# R7KA8M2AD register map
Vendor: Renesas Electronics Corporation; Series: RA8; File version: 1.10.02
CPU: CM85 r0p2, little endian, MPU, FPU, VTOR, 4 interrupt priority bits, 96 interrupts
Registers are 32-bit, read-write, reset 0x0 unless marked. A register's access mark holds for its fields unless they carry their own. Offsets are from the block's base; [hi:lo] are bit positions; {n}, {i} and the like mark numbered series; 'fields as' and 'values as' point back to an identical list.

## SCI0_B — Serial Communication Interface
Base 0x40358000
Same registers: SCI{n}_B {0x40358000+0x100*n} (n=1..9), SCI{n}_B_NS {0x50358000+0x100*n} (n=0..9)
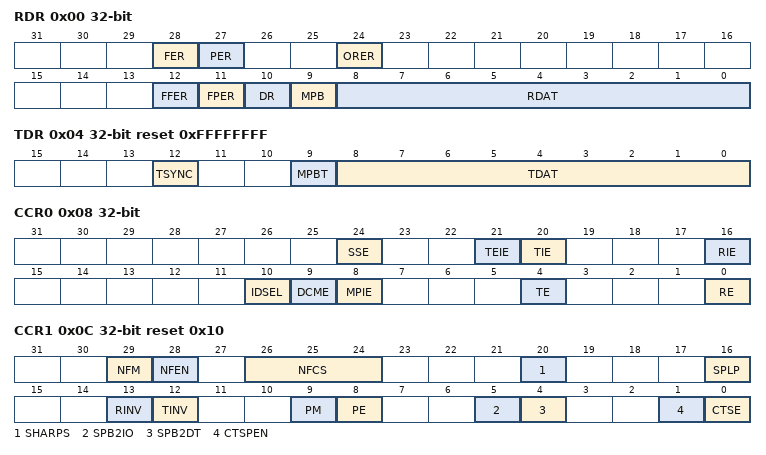
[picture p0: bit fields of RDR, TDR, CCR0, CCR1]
0x00 RDR ro — Receive Data Register
  [28] FER — Framing error flag
  [27] PER — Parity error flag
  [24] ORER — Overrun Error flag
  [12] FFER — FIFO framing error flag
    0=There is no framing error in the data read from the receive-FIFO; 1=There is framing error in the data read from the receive-FIFO
  [11] FPER — FIFO parity error flag
    0=There is no parity error in the data read from the receive-FIFO; 1=There is parity error in the data read from the receive-FIFO
  [10] DR — Receive data ready flag
  [9] MPB — Multi-processor flag
    0=Data transmission cycles; 1=ID transmission cycles
  [8:0] RDAT — Serial receive data
0x04 TDR reset 0xFFFFFFFF — Transmit Data Register
  [12] TSYNC — Transmit SYNC data
    0=The Start Bit is transmitted as DATA SYNC; 1=The Start Bit is transmitted as COMMAND SYNC
  [9] MPBT — Multi-processor transfer bit flag
    0=Data transmission cycles; 1=ID transmission cycles
  [8:0] TDAT — Serial transmit data
0x08 CCR0 — Common Control Register 0
  [24] SSE — SSn Pin Function Enable
    0=SSn pin function is disabled; 1=SSn pin function is enabled
  [21] TEIE — Transmit End Interrupt Enable
    0=SCIn_TEI interrupt request is disabled; 1=SCIn_TEI interrupt request is enabled
  [20] TIE — Transmit Interrupt Enable
    0=SCIn_TXI interrupt request is disabled; 1=SCIn_TXI interrupt request is enabled
  [16] RIE — Receive Interrupt Enable
    0=SCIn_RXI and SCIn_ERI interrupt requests are disabled; 1=SCIn_RXI and SCIn_ERI interrupt requests are enabled
  [10] IDSEL — ID Frame Select
    0=Compare data irrespective of the value of the MPB bit; 1=Compare data only when the MPB bit is 1 (ID frame)
  [9] DCME — Data Compare Match Enable
    0=Address match function is disabled; 1=Address match function is enabled
  [8] MPIE — Multi-Processor Interrupt Enable
    0=Non-multi-processor reception; 1=Multi-processor reception When the data with the multi-processor bit set to 0 is received, the data is not read, and setting the status flags to 1 is disabled. When the data with the multi-processor bit set to 1 is received, the MPIE bit is automatically cleared to 0, and non-multi-processor reception is resumed. If you want to continue receiving operation using the multiprocessor function, set this bit to 1 sufficiently earlier than receiving the STOP bit of the next received frame (consider the synchronization delay time).
  [4] TE — Transmit Enable
    0=Serial transmission is disabled; 1=Serial transmission is enabled
  [0] RE — Receive Enable
    0=Serial reception is disabled; 1=Serial reception is enabled
0x0C CCR1 reset 0x10 — Common Control Register 1
  [29] NFM — Noise Filter Mode
    0=3-point matching mode; 1=Majority vote mode
  [28] NFEN — Digital Noise Filter Function Enable
    0=In Asynchronous, Manchester, Simple LIN modes: Disable noise cancellation function for RXDn input signal In Simple IIC mode: Disable noise cancellation function for SCLn and SDAn input signals; 1=In Asynchronous, Manchester, Simple LIN modes: Enable noise cancellation function for RXDn input signal In Simple IIC mode: Enable noise cancellation function for SCLn and SDAn input signals
  [26:24] NFCS — Noise Filter Clock Select
    0=The base clock signal divided by 1; 1=The on-chip baud rate generator source clock divided by 1; 2=The on-chip baud rate generator source clock divided by 2; 3=The on-chip baud rate generator source clock divided by 4; 4=The on-chip baud rate generator source clock divided by 8; other=others (Setting prohibited)
  [20] SHARPS — Half-Duplex Communication Select
    0=TXDn pin, RXDn pin independent; 1=TXDn/RXDn pin combination use (half-duplex communication using TXDn pin)
  [16] SPLP — Loopback Control
    0=Normal mode; 1=Loopback mode
  [13] RINV — RXD Invert
    0=Received data from RXDn is not inverted and input; 1=Received data from RXDn is inverted and input
  [12] TINV — TXD Invert
    0=Transmit data is not inverted and output to TXDn; 1=Transmit data is inverted and output to TXDn
  [9] PM — Parity Mode
    0=Selects even parity; 1=Selects odd parity
  [8] PE — Parity Enable
    0=When transmitting: Do not add parity bit When receiving: Do not check parity bit; 1=When transmitting: Add parity bit When receiving: Check parity bit
  [5] SPB2IO — Serial Port Break I/O
    0=The value of SPB2DT bit is not output in TXDn pin; 1=The value of SPB2DT bit is output in TXDn pin
  [4] SPB2DT — Serial Port Break Data Select
    0=When TINV is 0, low level is output in TXDn pin. When TINV is 1, high level is output in TXDn pin.; 1=When TINV is 0, high level is output in TXDn pin. When TINV is 1, low level is output in TXDn pin.
  [1] CTSPEN — CTS External Pin Enable
    0=Alternate setting to use CTS and RTS functions as either 1 pin; 1=Dedicated setting for separately using CTS and RTS functions with 2 pins
  [0] CTSE — CTS Enable
    0=CTS function is disabled (RTS output function is enabled); 1=CTS function is enabled
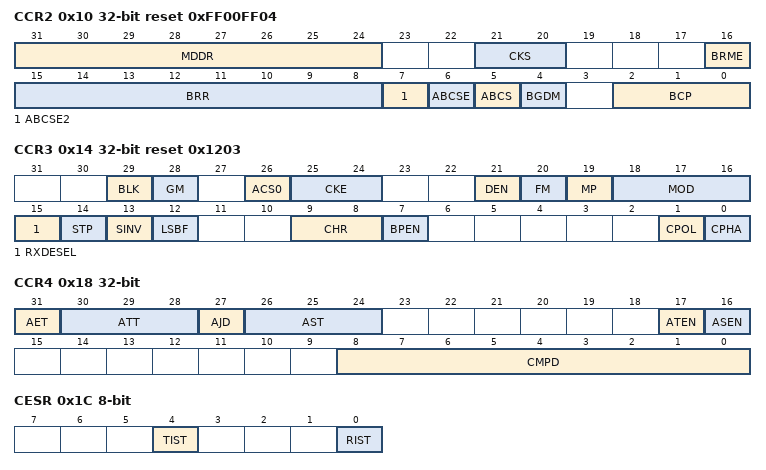
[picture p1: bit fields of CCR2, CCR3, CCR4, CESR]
0x10 CCR2 reset 0xFF00FF04 — Common Control Register 2
  [31:24] MDDR — Modulation Duty Setting
  [21:20] CKS — Clock Select
    0=TCLK clock (n = 0); 1=TCLK/4 clock (n = 1); 2=TCLK/16 clock (n = 2); 3=TCLK/64 clock (n = 3)
  [16] BRME — Bit Rate Modulation Enable
    0=Bit rate modulation function is disabled; 1=Bit rate modulation function is enabled
  [15:8] BRR — Bit Rate Setting
  [7] ABCSE2 — Asynchronous Mode Extended Base Clock Select 2
    0=Clock cycles for 1-bit period is decided with combination between CCR2.BGDM and CCR2.ABCS; 1=Baud rate is 4 base clock cycles for 1-bit period and the clock of a double frequency is output from the baud rate generator
  [6] ABCSE — Asynchronous Mode Extended Base Clock Select
    0=Clock cycles for 1-bit period is determined by combination between CCR2.BGDM and CCR2.ABCS; 1=Baud rate is 6 base clock cycles for 1-bit period and the clock of a double frequency is output from the baud rate generator
  [5] ABCS — Asynchronous Mode Base Clock Select
    0=Selects 16 base clock cycles for 1-bit period; 1=Selects 8 base clock cycles for 1-bit period
  [4] BGDM — Baud Rate Generator Double-Speed Mode Select
    0=Baud rate generator outputs the clock with single frequency; 1=Baud rate generator outputs the clock with doubled frequency
  [2:0] BCP — Base Clock Pulse
    0=93 clock cycles (S = 93); 1=128 clock cycles (S = 128); 2=186 clock cycles (S = 186); 3=512 clock cycles (S = 512); 4=32 clock cycles (S = 32) (Initial value); 5=64 clock cycles (S = 64); 6=372 clock cycles (S = 372); 7=256 clock cycles (S = 256)
0x14 CCR3 reset 0x1203 — Common Control Register 3
  [29] BLK — Block Transfer Mode
    0=Non-block transfer mode operation; 1=Block transfer mode operation
  [28] GM — GSM Mode
    0=Non-GSM mode operation; 1=GSM mode operation
  [26] ACS0 — Asynchronous Mode Clock Source Select
    0=External clock input; 1=Logical AND of compare matches output from the internal GPT
  [25:24] CKE — Clock Enable
    0=In Asynchronous mode:On-chip baud rate generatorThe SCKn pin is available for use as an I/O port in accord with the I/O port settings. In Manchester mode and Simple LIN mode:On-chip baud rate generatorThe SCKn pin functions as I/O port. In Clock synchronous mode and Simple SPI mode:Internal clock (master operation)The SCKn pin functions as the clock output pin. In Smart card interface mode and when CCR3.GM = 0:Output disabled (the SCKn pin is available for use as an I/O port in accord with the I/O port settings). In Smart card interface mode and when CCR3.GM = 1:Output fixed low; 1=In Asynchronous mode:On-chip baud rate generatorThe clock with the same frequency as the bit rate is output from the SCKn pin. In Manchester mode and Simple LIN mode:Prohibited In Clock synchronous mode and Simple SPI mode:Internal clock (master operation)The SCKn pin functions as the clock output pin. In Smart card interface mode and when CCR3.GM = 0:Clock output In Smart card interface mode and when CCR3.GM = 1:Clock output; 2=In Asynchronous mode:External clock or GPT clock When using the external clock16 times the bit rate should be input from the SCKn pin when CCR2.ABCS bit is 0. Input a clock signal with a frequency 8 times the bit rate when the CCR2.ABCS bit is 1.When using the GPT clockThe SCKn pin is available for use as an I/O port in accord with the I/O port settings when the GPT clock is used. In Manchester mode and Simple LIN mode:Prohibited In Clock synchronous mode and Simple SPI mode:External clock (slave operation)The SCKn pin functions as the clock input pin. In Smart card interface mode and when CCR3.GM = 0:Prohibited In Smart card interface mode and when CCR3.GM = 1:Output fixed high; 3=In Asynchronous mode:External clock or GPT clock When using the external clock16 times the bit rate should be input from the SCKn pin when CCR2.ABCS bit is 0. Input a clock signal with a frequency 8 times the bit rate when the CCR2.ABCS bit is 1.When using the GPT clock The SCKn pin is available for use as an I/O port in accord with the I/O port settings when the GPT clock is used. In Manchester mode and Simple LIN mode:Prohibited In Clock synchronous mode and Simple SPI mode:External clock (slave operation)The SCKn pin functions as the clock input pin. In Smart card interface mode and when CCR3.GM = 0:Prohibited In Smart card interface mode and when CCR3.GM = 1:Clock output
  [21] DEN — Driver Enable
    0=RS-485 driver control function disabled; 1=RS-485 driver control function enabled
  [20] FM — FIFO Mode Select
    0=TDR register and RDR register are non-FIFO buffer configuration; 1=TDR register and RDR register are FIFO buffer configuration
  [19] MP — Multi-Processor Mode
    0=Multi-processor communications function is disabled; 1=Multi-processor communications function is enabled
  [18:16] MOD — Communication Mode Select
    0=Asynchronous mode (multi-processor mode); 1=Smart card interface mode; 2=Clock synchronous mode; 3=Simple SPI mode; 4=Simple IIC mode; 5=Manchester mode; 6=Simple LIN mode; 7=Setting prohibited
  [15] RXDESEL — Asynchronous Start Bit Edge Detection Select
    0=The low level on the RXDn pin is detected as the start bit; 1=A falling edge on the RXDn pin is detected as the start bit
  [14] STP — Stop Bit Length
    0=1 stop bit/break delimiter length is 1-bit; 1=2 stop bits/break delimiter length is 2-bit
  [13] SINV — Transmitted/Received Data Invert
    0=TDR contents are transmitted to TSR as is. RSR contents are stored to RDR as is.; 1=TDR contents are inverted before being transmitted to TSR. RSR contents are inverted and stored to RDR.
  [12] LSBF — LSB First select
    0=MSB-first; 1=LSB-first
  [9:8] CHR — Character Length
    0=Transmit/receive in 9-bit data length; 1=Transmit/receive in 9-bit data length; 2=Transmit/receive in 8-bit data length (initial value); 3=Transmit/receive in 7-bit data length
  [7] BPEN — Synchronizer Bypass Enable
    0=Synchronizer circuit is not bypassed; 1=Synchronizer circuit is bypassed
  [1] CPOL — Clock Polarity Select
    0=SCKn in idle state is 0; 1=SCKn in idle state is 1
  [0] CPHA — Clock Phase Select
    0=Data is sampled at an odd edge and changes at an even edge (clock is delayed); 1=Data changes at an odd edge and is sampled at an even edge (clock is not delayed)
0x18 CCR4 — Common Control Register 4
  [31] AET — Adjustment Edge for Transmit Timing
    0=When CCR1.TINV is 0, adjust the rising edge timing. When CCR1.TINV is 1, adjust the falling edge timing.; 1=When CCR1.TINV is 0, adjust the falling edge timing. When CCR1.TINV is 1, adjust the rising edge timing.
  [30:28] ATT — Adjustment Value for Transmit Timing
  [27] AJD — Adjustment Direction for Receive Sampling Timing
    0=The sampling timing is adjusted backward to the middle of bit; 1=The sampling timing is adjusted forward to the middle of bit
  [26:24] AST — Adjustment Value for Receive Sampling Timing
    {v}={v+1}-TCLK delay (v=0..3); other=Others (Setting prohibited)
  [17] ATEN — Adjust Transmit Timing Enable
    0=Adjust transmit timing disabled; 1=Adjust transmit timing enabled
  [16] ASEN — Adjust Receive Sampling Timing Enable
    0=Adjust sampling timing disabled; 1=Adjust sampling timing enabled
  [8:0] CMPD — Compare Match Data
0x1C CESR 8-bit ro — Communication Enable Status Register
  [4] TIST — TE Internal Status
    0=TE signal internal state value 0; 1=TE signal internal state value 1
  [0] RIST — RE Internal Status
    0=RE signal internal state value 0; 1=RE signal internal state value 1
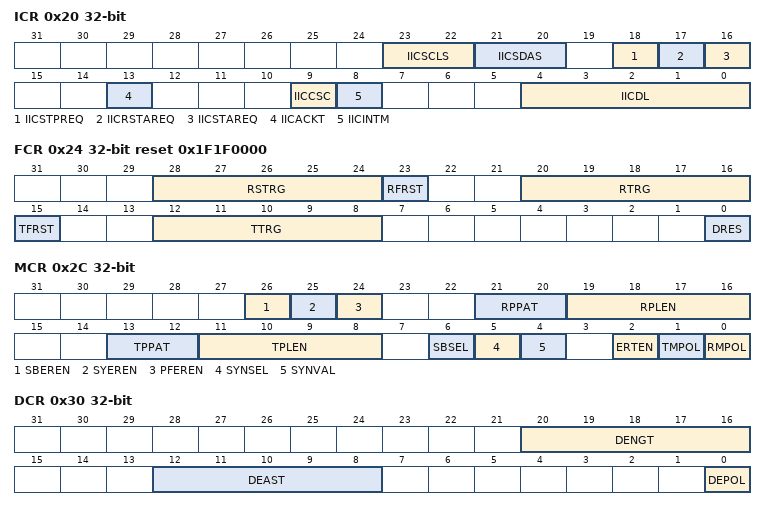
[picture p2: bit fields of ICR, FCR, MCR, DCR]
0x20 ICR — Simple IIC Control Register
  [23:22] IICSCLS — SCL Output Select
    0=Serial clock output; 1=Generate a start, restart, or stop condition; 2=Output the low level on the SCLn pin; 3=Place the SCLn pin in the high-impedance state
  [21:20] IICSDAS — SDA Output Select
    0=Serial data output; 1=Generate a start, restart, or stop condition; 2=Output the low level on the SDAn pin; 3=Place the SDAn pin in the high-impedance state
  [18] IICSTPREQ — Stop Condition Generation
    0=A stop condition is not generated; 1=A stop condition is generated
  [17] IICRSTAREQ — Restart Condition Generation
    0=A restart condition is not generated; 1=A restart condition is generated
  [16] IICSTAREQ — Start Condition Generation
    0=A start condition is not generated; 1=A start condition is generated
  [13] IICACKT — ACK Transmission Data
    0=ACK transmission; 1=NACK transmission and reception of ACK/NACK
  [9] IICCSC — Clock Synchronization
    0=No synchronization with the clock signal; 1=Synchronization with the clock signal
  [8] IICINTM — IIC Interrupt Mode Select
    0=Use ACK/NACK interrupts; 1=Use reception and transmission interrupts
  [4:0] IICDL — SDA Delay Output Select
0x24 FCR reset 0x1F1F0000 — FIFO Control Register
  [28:24] RSTRG — RTS Output Active Trigger Number Select
  [23] RFRST wo — Receive FIFO Data Register Reset
    0=When set, this bit is invalid and does not affect operation; 1=The number of data stored in Receive-FIFO(RDR register) is 0
  [20:16] RTRG — Receive FIFO Data Trigger Number
  [15] TFRST wo — Transmit FIFO Data Register Reset
    0=When set, this bit is invalid and does not affect operation; 1=The number of data stored in Transmit-FIFO (TDR register) is 0
  [12:8] TTRG — Transmit FIFO Data Trigger Number
  [0] DRES — Receive Data Ready Error Select Bit
    0=Reception data full interrupt (SCIn_RXI); 1=Receive error interrupt (SCIn_ERI)
0x2C MCR — Manchester Control Register
  [26] SBEREN — Start Bit Error Enable
    0=Does not handle a start bit error as an interrupt source; 1=Handles a start bit error as an interrupt source
  [25] SYEREN — Receive SYNC Error Enable
    0=Does not handle a receive SYNC error as an interrupt source; 1=Handles a receive SYNC error as an interrupt source
  [24] PFEREN — Preface Error Enable
    0=Does not handle a preface error as an interrupt source; 1=Handles a preface error as an interrupt source
  [21:20] RPPAT — Receive Preface Pattern
    0=ALL ZERO; 1=ZERO ONE; 2=ONE ZERO; 3=ALL ONE
  [19:16] RPLEN — Receive Preface Length
    0=Disables the receive preface generation; other=Others (Receive preface length (bit length))
  [13:12] TPPAT — Transmit Preface Pattern
    0=ALL ZERO; 1=ZERO ONE; 2=ONE ZERO; 3=ALL ONE
  [11:8] TPLEN — Transmit Preface Length
    0=Disables the transmit preface generation; other=Others (Transmit preface length (bit length))
  [6] SBSEL — Start Bit Select
    0=The start bit area consists of one bit; 1=The start bit area consists of three bits (COMMAND SYNC or DATA SYNC)
  [5] SYNSEL — SYNC Select
    0=The start bit pattern is set with the SYNVAL bit; 1=The start bit pattern is set with the TSYNC bit
  [4] SYNVAL — SYNC value Setting
  [2] ERTEN — Manchester Edge Retiming Enable
    0=Disables the receive retiming function; 1=Enables the receive retiming function
  [1] TMPOL — Polarity of Transmit Manchester Code
    0=Logic 0 is coded as a zero-to-one transition in Manchester code Logic 1 is coded as a one-to-zero transition in Manchester code; 1=Logic 0 is coded as a one-to-zero transition in Manchester code Logic 1 is coded as a zero-to-one transition in Manchester code
  [0] RMPOL — Polarity of Received Manchester Code
    values as TMPOL
0x30 DCR — Driver Control Register
  [20:16] DENGT — Driver Negate Time
  [12:8] DEAST — Driver Assertion Time
  [0] DEPOL — Driver Effective Polarity Select
    0=The DEn signal is active-high; 1=The DEn signal is active-low
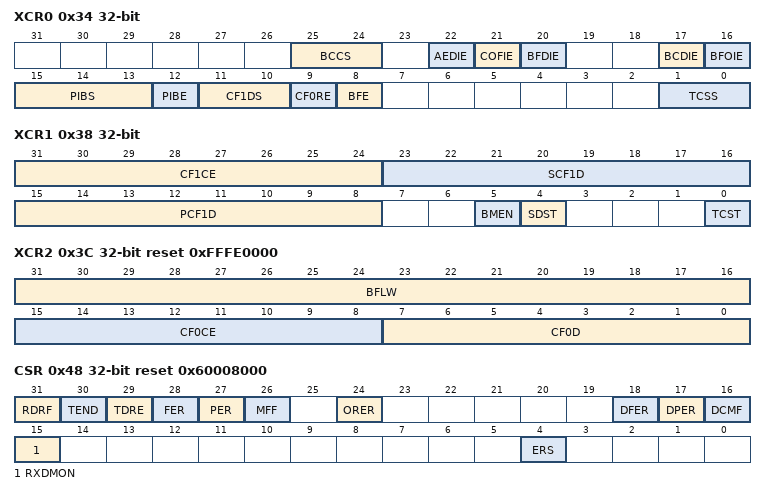
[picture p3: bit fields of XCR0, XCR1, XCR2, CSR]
0x34 XCR0 — Simple LIN Control Register 0
  [25:24] BCCS — Bus Conflict Detection Clock Selection
    0=Base clock; 1=Base clock/2; 2=Base clock/4; 3=Setting prohibited
  [22] AEDIE — Active Edge Detection Interrupt Enable
    0=Active edge detection interrupt disabled; 1=Active edge detection interrupt enabled
  [21] COFIE — Counter Overflow Interrupt Enable
    0=Counter overflow is not included in SCIn_ERI interrupt factor; 1=Counter overflow is included in SCIn_ERI interrupt factor
  [20] BFDIE — Break Field Detection Interrupt Enable
    0=Break Field detection interrupt disabled; 1=Break Field detection interrupt enabled
  [17] BCDIE — Bus Conflict Detection Interrupt Enable
    0=Bus conflict detection is not included in SCIn_ERI interrupt factor; 1=Bus conflict detection is included in SCIn_ERI interrupt factor
  [16] BFOIE — Break Field Output Completion Interrupt Enable
    0=Break Field output completion is not included in SCIn_TXI interrupt factor; 1=Break Field output completion is included in SCIn_TXI interrupt factor
  [15:13] PIBS — Priority Interrupt Bit Select
    {v}=Bit {v} of Control Field 1 (v=0..7)
  [12] PIBE — Priority Interrupt Bit Enable
    0=Priority interrupt bit disabled; 1=Priority interrupt bit enabled
  [11:10] CF1DS — Control Field1 Compare Data Select
    0=Select XCR1.PCF1D[7:0] as the compare data; 1=Select XCR1.SCF1D[7:0] as the compare data; 2=Select both XCR1.PCF1D[7:0] and XCR1.SCF1D[7:0] as the compare data; 3=Setting prohibited
  [9] CF0RE — Control Field 0 Enable
    0=No Control Field 0; 1=With Control Field 0
  [8] BFE — Break Field Enable
    0=No Break Field; 1=With Break Field
  [1:0] TCSS — Timer Count Clock Source Selection
    1=TCLK/4; 2=TCLK/16; 3=TCLK/64
0x38 XCR1 — Simple LIN Control Register 1
  [31:24] CF1CE — Control Field 1 Compare Bit Enable
    0=Control Field 1 bit N compare disabled; 1=Control Field 1 bit N compare enabled
  [23:16] SCF1D — Secondary Compare Data for Control Field 1
  [15:8] PCF1D — Priority Compare Data for Control Field 1
  [5] BMEN — Bit Rate Measurement Enable
    0=Bit rate measurement disabled; 1=Bit rate measurement enabled
  [4] SDST — Start Frame Detection Enable
    0=Start Frame/Break Field detection disabled; 1=Start Frame/Break Field detection enabled
  [0] TCST — Break Field Output Timer Count Start Trigger
    0=Break Field output timer count stopped; 1=Break Field output timer count start
0x3C XCR2 reset 0xFFFE0000 — Simple LIN Control Register 2
  [31:16] BFLW — Break Field Length Setting
  [15:8] CF0CE — Control Field 0 Compare Bit Enable
    0=Control Field 0 bit N compare disabled; 1=Control Field 0 bit N compare enabled
  [7:0] CF0D — Control Field 0 Compare Data
0x48 CSR ro reset 0x60008000 — Common Status Register
  [31] RDRF — Receive Data Full Flag
    0=Non-FIFO selected (CCR3.FM = 0): No received data is in RDR register FIFO selected (CCR3.FM = 1): The quantity of receive data written in receive-FIFO falls below the specified receive triggering number; 1=Non-FIFO selected (CCR3.FM = 0): Received data is in RDR register FIFO selected (CCR3.FM = 1): The quantity of receive data written in receive-FIFO is equal to or greater than the specified receive triggering number
  [30] TEND — Transmit End Flag
    0=A character is being transmitted or standing by for transmission; 1=Character transfer has been completed, or sending Break Field
  [29] TDRE — Transmit Data Empty Flag
    0=Non-FIFO selected (CCR3.FM = 0): Transmit data is in TDR register FIFO selected (CCR3.FM = 1): The quantity of transmit data written in transmit-FIFO exceeds the specified transmit triggering number; 1=Non-FIFO selected (CCR3.FM = 0): No transmit data is in TDR register FIFO selected (CCR3.FM = 1): The quantity of transmit data written in transmit-FIFO is equal to or less than the specified transmit triggering number
  [28] FER — Framing Error Flag
    0=Non-FIFO selected (CCR3.FM = 0): No framing error occurred FIFO selected (CCR3.FM = 1): No framing error in all received data in receive-FIFO; 1=Non-FIFO selected (CCR3.FM = 0): A framing error has occurred FIFO selected (CCR3.FM = 1): One or more framing errors occurred in received data in receive-FIFO
  [27] PER — Parity Error Flag
    0=Non-FIFO selected (CCR3.FM = 0): No parity error occurred FIFO selected (CCR3.FM = 1): No parity error in all received data in receive-FIFO; 1=Non-FIFO selected (CCR3.FM = 0): A parity error has occurred FIFO selected (CCR3.FM = 1): One or more parity errors occurred in received data in receive-FIFO
  [26] MFF — Mode Fault Error Flag
    0=No mode fault error; 1=Mode fault error
  [24] ORER — Overrun Error Flag
    0=No overrun error occurred; 1=An overrun error has occurred
  [18] DFER — Data Compare Match Framing Error Flag
    0=No framing error occurred at address match detection; 1=A framing error has occurred at address match detection
  [17] DPER — Data Compare Match Parity Error Flag
    0=No parity error occurred at address match detection; 1=A parity error has occurred at address match detection
  [16] DCMF — Data Compare Match Flag
    0=No matched; 1=Matched
  [15] RXDMON — Serial Input Data Monitor Bit
    0=When RINV is 0, RXDn pin is the low level. When RINV is 1, RXDn pin is the high level.; 1=When RINV is 0, RXDn pin is the high level. When RINV is 1, RXDn pin is the low level.
  [4] ERS — Error Signal Status Flag
    0=Error signal low not responded; 1=Error signal low responded
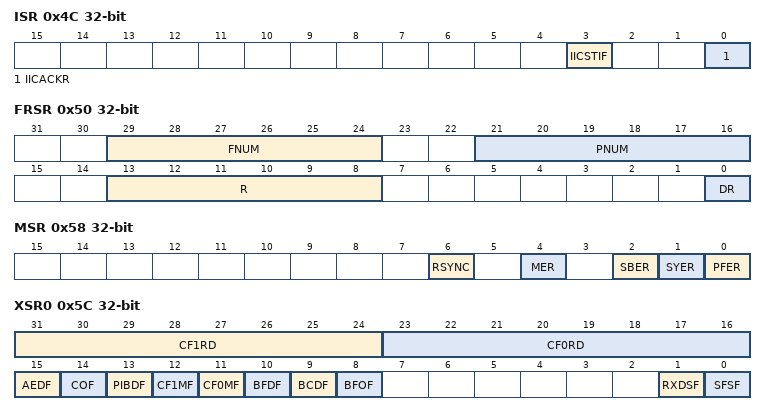
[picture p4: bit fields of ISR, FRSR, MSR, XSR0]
0x4C ISR ro — Simple IIC Status Register
  [3] IICSTIF — Issuing of Start, Restart, or Stop Condition Completed Flag
    0=There are no requests for generating conditions or a condition is being generated; 1=A start, restart, or stop condition is completely generated
  [0] IICACKR — ACK Reception Data Flag
    0=ACK received; 1=NACK received
0x50 FRSR ro — FIFO Receive Status Register
  [29:24] FNUM — Framing Error Count
  [21:16] PNUM — Parity Error Count
  [13:8] R — Receive-FIFO Data Count
  [0] DR — Receive Data Ready Flag
    0=Receiving is in progress, or no received data remains in the receive-FIFO after a successful reception (receive-FIFO is empty); 1=The following receive data is not received for a fixed period after storing data under the threshold in the receive-FIFO
0x54 FTSR ro — FIFO Transmit Status Register
  [5:0] T — Transmit-FIFO Data Count
0x58 MSR ro — Manchester Status Register
  [6] RSYNC — Receive SYNC Data Bit
    0=The received start bit is DATA SYNC; 1=The received start bit is COMMAND SYNC
  [4] MER — Manchester Error Flag
    0=No Manchester error occurred; 1=Manchester error has occurred
  [2] SBER — Start Bit Error Flag
    0=No start bit error detected; 1=Start bit error detected
  [1] SYER — SYNC Error Flag
    0=No receive SYNC error detected; 1=Receive SYNC error detected
  [0] PFER — Preface Error Flag
    0=No preface error detected; 1=Preface error detected
0x5C XSR0 ro — Simple LIN Status Register 0
  [31:24] CF1RD — Control Field 1 received data
  [23:16] CF0RD — Control Field 0 received data
  [15] AEDF — Active Edge Detection Flag
    0=No valid edge detected; 1=Detected a valid edge
  [14] COF — Counter Overflow Flag
    0=Break Field detection counter has not overflowed; 1=Break Field detection counter overflowed
  [13] PIBDF — Priority Interrupt Bit Detection Flag
    0=Priority interrupt bit is not detected; 1=Priority interrupt bit is detected
  [12] CF1MF — Control Field 1 Compare Match Flag
    0=Control Field 1 received data does not match the setting data; 1=Control Field 1 received data matches the setting data
  [11] CF0MF — Control Field 0 Compare Match Flag
    0=Control Field 0 received data does not match the setting data; 1=Control Field 0 received data matches the setting data
  [10] BFDF — Break Field Detection Flag
    0=Break Field is not detected; 1=Break Field is detected
  [9] BCDF — Bus Conflict Detection Flag
    0=No bus collision detected; 1=Detected a bus collision
  [8] BFOF — Break Field Output Completion Flag
    0=Break Field is being output or is not being output; 1=Completed BF output
  [1] RXDSF — RXDn Input Status Flag
    0=RXDn input to SCI is enabled; 1=RXDn input to SCI is disabled
  [0] SFSF — Start Frame Status Flag
    0=Start Frame detection disabled or Start Frame detection complete; 1=Before Start Frame detection or during detection
0x60 XSR1 ro — Simple LIN Status Register 1
  [15:0] TCNT — Timer Count Capture Value
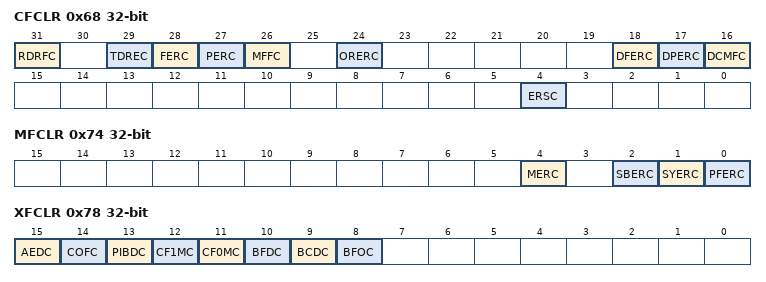
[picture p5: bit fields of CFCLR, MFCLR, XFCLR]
0x68 CFCLR wo — Common Flag Clear Register
  [31] RDRFC — RDRF Clear Bit
  [29] TDREC — TDRE Clear Bit
  [28] FERC — FER Clear Bit
  [27] PERC — PER Clear Bit
  [26] MFFC — MFF Clear Bit
  [24] ORERC — ORER Clear Bit
  [18] DFERC — DFER Clear Bit
  [17] DPERC — DPER Clear Bit
  [16] DCMFC — DCMF Clear Bit
  [4] ERSC — ERS Clear Bit
0x6C ICFCLR wo — Simple IIC Flag Clear Register
  [3] IICSTIFC — IICSTIF Clear Bit
0x70 FFCLR wo — FIFO Flag Clear Register
  [0] DRC — DR Clear Bit
0x74 MFCLR wo — Manchester Flag Clear Register
  [4] MERC — MER Clear Bit
  [2] SBERC — SBER Clear Bit
  [1] SYERC — SYER Clear Bit
  [0] PFERC — PFER Clear Bit
0x78 XFCLR wo — Simple LIN Flag Clear Register
  [15] AEDC — AEDF Clear Bit
  [14] COFC — COFF Clear Bit
  [13] PIBDC — PIBDF Clear Bit
  [12] CF1MC — CF1MF Clear Bit
  [11] CF0MC — CF0MF Clear Bit
  [10] BFDC — BFDF Clear Bit
  [9] BCDC — BCDF Clear Bit
  [8] BFOC — BFOF Clear Bit
